# cyw20829 register map
Vendor: Infineon Technologies; Series: CYW20829; File version: 1.0
CPU: CM33 r0p1, little endian, MPU, no FPU, VTOR, 3 interrupt priority bits
Registers are 32-bit, read-write, reset 0x0 unless marked. A register's access mark holds for its fields unless they carry their own. Offsets are from the block's base; [hi:lo] are bit positions; lines under a group give offsets from that group; {n}, {i} and the like mark numbered series; 'fields as' and 'values as' point back to an identical list.

## MS_CTL_1_2 — Master control registers
Base 0x401C4000
{0x0+0x10*i} MS[{i}] (i=0..31) group — Master protection context control
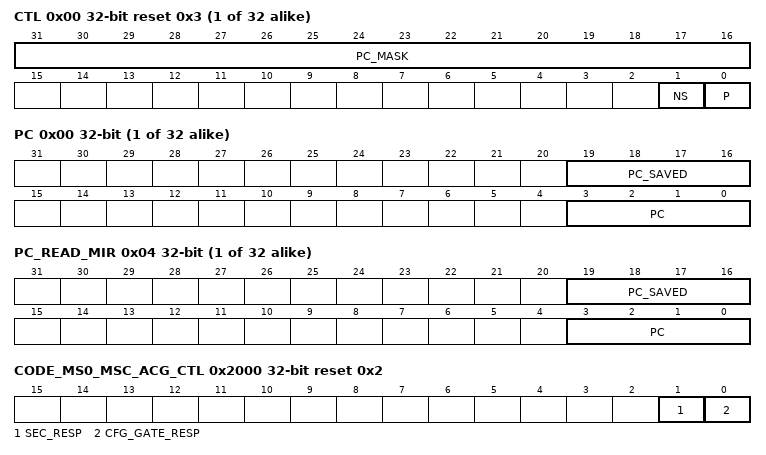
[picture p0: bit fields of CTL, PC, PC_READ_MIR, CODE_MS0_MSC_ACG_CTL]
  0x00 CTL reset 0x3 — Master 'x' protection context control
    [31:16] PC_MASK — Protection context mask for protection contexts '15' down to '0'. Bit PC_MASK[i] indicates if the MS_PC_STRUCT[x].PC[3:0] protection context field can be set to the value 'i': - PC_MASK[i] is '0': MS_PC_STRUCT[x].PC[3:0] can NOT be set to 'i'; and PC[3:0] is not changed. - PC_MASK[i] is '1': MS_PC_STRUCT[x].PC[3:0] can be set to 'i'. Note: When CM33_0 CM33_PC_CTL.VALID[i] is '1' (the associated protection context handler is valid), write transfers to PC_MASK[i] always write '0', regardless of data written. This ensures that when valid protection context handlers are used to enter protection contexts 0, 1, 2 or 3 through HW (HW modifies MS_PC_STRUCT[x].PC[3:0] on entry of the handler), it is NOT possible for SW to enter those protection contexts.
    [1] NS — Master security controller configuration. 0: Bus master is secure. Master can send both secure and non-secure transfers. Accesses to secure addresses are not blocked and the security flag, HNONSEC, is set accordingly. 1: Bus master is non-secure. Master can send only non-secure transfers. Access to secure addresses, that is, outside the Uncheck regions, are blocked.
    [0] P — Privileged setting ('0': user mode; '1': privileged mode). Notes: This field is ONLY used for masters that do NOT provide their own user/privileged access control attribute. The default/reset field value provides privileged mode access capabilities.
{0x1000+0x10*i} MS_PC[{i}] (i=0..31) group — Master protection context value
  0x00 PC — Master 'x' protection context value
    [19:16] PC_SAVED — Saved protection context. Modifications to this field are constrained by the associated MS_CTL_STRUCT[x].CTL.PC_MASK. Note: this field is ONLY used by the CM33_0.
    [3:0] PC — Active protection context (PC). Modifications to this field are constrained by the associated MS_CTL_STRUCT[x].CTL.PC_MASK value. PC[3:0] can be set to 'i' only if the corresponding mask bit (PC_MASK[i]) is '1'. The CM33_0 PC register is special: the PC field is modifiable by BOTH HW and SW (for all other masters, the PC field is modifiable by SW ONLY. For CM33_0 PC field HW modifications, the following holds: * On entry of a CM33_PC0/1/2/3_HANDLER exception/interrupt handler: IF (the new PC is the same as MS_PC_STRUCT[0].PC) PC is not affected; PC_SAVED is not affected. ELSE IF (CM33_PC_CTL.VALID[MS_PC_STRUCT[0].PC]) An AHB5 bus error is generated for the exception handler fetch; PC is not affected; PC_SAVED is not affected. ELSE PC = 'new PC'; PC_SAVED = PC (push operation). * On entry of any other exception/interrupt handler: PC = PC_SAVED; PC_SAVED is not affected (pop operation). Note that the CM33_PC0/1/2/3_HANDLER and CM33_PC_CTL registers are part of mxcm33 MMIO registers. Note: this field is NOT used by the DW controllers, DMA controllers as they inherit the protection context from master that configures the corresponding channel.
  0x04 PC_READ_MIR ro — Master 'x' protection context value read mirror register
    [19:16] PC_SAVED — Read-only mirror of PC.PC_SAVED
    [3:0] PC — Read-only mirror of PC.PC
0x2000 CODE_MS0_MSC_ACG_CTL reset 0x2 — CODE_MS0 master security Controller & ACG configuration
  [1] SEC_RESP — Reseponse type when transfers are not allowed by MSC. 0: Read as zero, write ignore. 1: Error response.
  [0] CFG_GATE_RESP — Response type when the ACG is blocking the incoming transfers: 0: Waited transfer 1: Error response
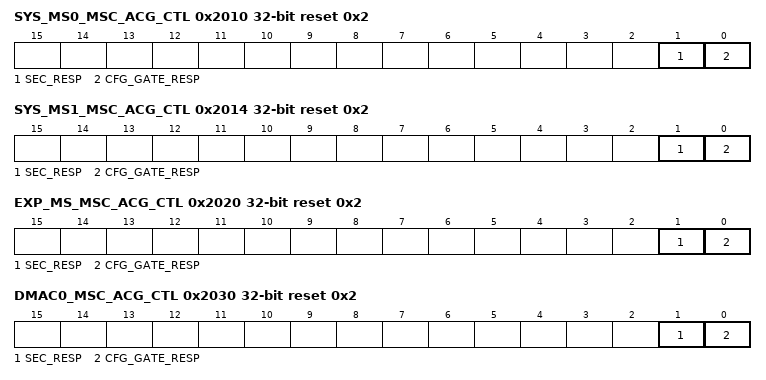
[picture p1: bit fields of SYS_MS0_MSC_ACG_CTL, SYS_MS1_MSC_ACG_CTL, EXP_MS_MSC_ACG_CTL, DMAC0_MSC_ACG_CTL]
0x2010 SYS_MS0_MSC_ACG_CTL reset 0x2 — SYS_MS0 master security Controller & ACG configuration
  fields as CODE_MS0_MSC_ACG_CTL
0x2014 SYS_MS1_MSC_ACG_CTL reset 0x2 — SYS_MS1 master security Controller & ACG configuration
  fields as CODE_MS0_MSC_ACG_CTL
0x2020 EXP_MS_MSC_ACG_CTL reset 0x2 — EXP_MS master security Controller & ACG configuration
  fields as CODE_MS0_MSC_ACG_CTL
0x2030 DMAC0_MSC_ACG_CTL reset 0x2 — DMAC-0 master security Controller & ACG configuration
  fields as CODE_MS0_MSC_ACG_CTL
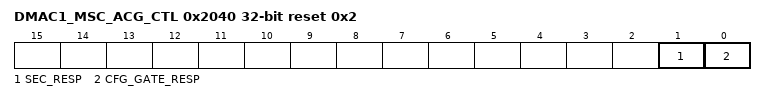
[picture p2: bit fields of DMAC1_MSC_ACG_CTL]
0x2040 DMAC1_MSC_ACG_CTL reset 0x2 — DMAC-1 master security Controller & ACG configuration
  fields as CODE_MS0_MSC_ACG_CTL
